# iostm32f205zx register map
Registers are 32-bit, access not given, no defined reset value unless marked. A register's access mark holds for its fields unless they carry their own. Addresses are absolute; registers are grouped by the start of their names; [hi:lo] are bit positions; {n}, {i} and the like mark numbered series.

## ADC2
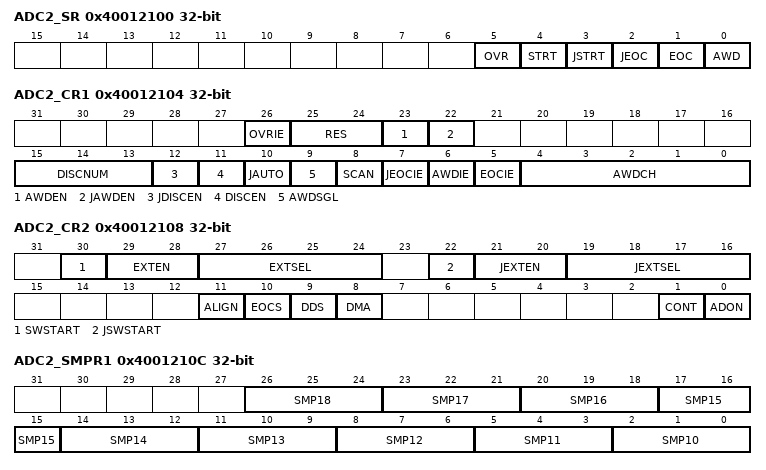
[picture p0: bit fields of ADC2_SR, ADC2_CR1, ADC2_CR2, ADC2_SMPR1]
0x40012100 ADC2_SR
  [5] OVR, [4] STRT, [3] JSTRT, [2] JEOC, [1] EOC, [0] AWD
0x40012104 ADC2_CR1
  [26] OVRIE, [25:24] RES, [23] AWDEN, [22] JAWDEN, [15:13] DISCNUM, [12] JDISCEN, [11] DISCEN, [10] JAUTO, [9] AWDSGL, [8] SCAN, [7] JEOCIE, [6] AWDIE, [5] EOCIE, [4:0] AWDCH
0x40012108 ADC2_CR2
  [30] SWSTART, [29:28] EXTEN, [27:24] EXTSEL, [22] JSWSTART, [21:20] JEXTEN, [19:16] JEXTSEL, [11] ALIGN, [10] EOCS, [9] DDS, [8] DMA, [1] CONT, [0] ADON
0x4001210C ADC2_SMPR1
  [3n-28:3n-30] SMP{n} (n=10..18)
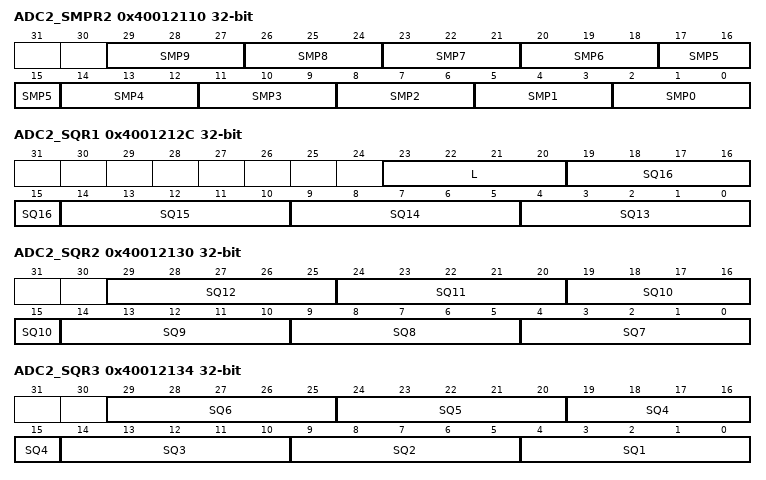
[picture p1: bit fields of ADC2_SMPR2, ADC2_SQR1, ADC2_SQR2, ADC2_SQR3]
0x40012110 ADC2_SMPR2
  [3n+2:3n] SMP{n} (n=0..9)
{0x40012110+4i} ADC2_JOFR{i} (i=1..4)
  [11:0] JOFFSET
0x40012124 ADC2_HTR
  [11:0] HT
0x40012128 ADC2_LTR
  [11:0] LT
0x4001212C ADC2_SQR1
  [23:20] L, [5n-61:5n-65] SQ{n} (n=13..16)
0x40012130 ADC2_SQR2
  [5n-31:5n-35] SQ{n} (n=7..12)
0x40012134 ADC2_SQR3
  [5n-1:5n-5] SQ{n} (n=1..6)
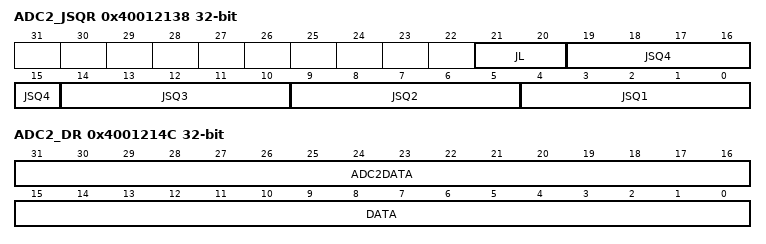
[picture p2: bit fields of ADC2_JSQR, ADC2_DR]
0x40012138 ADC2_JSQR
  [21:20] JL, [5n-1:5n-5] JSQ{n} (n=1..4)
{0x40012138+4i} ADC2_JDR{i} (i=1..4)
  [15:0] JDATA
0x4001214C ADC2_DR
  [31:16] ADC2DATA, [15:0] DATA

## ADC3
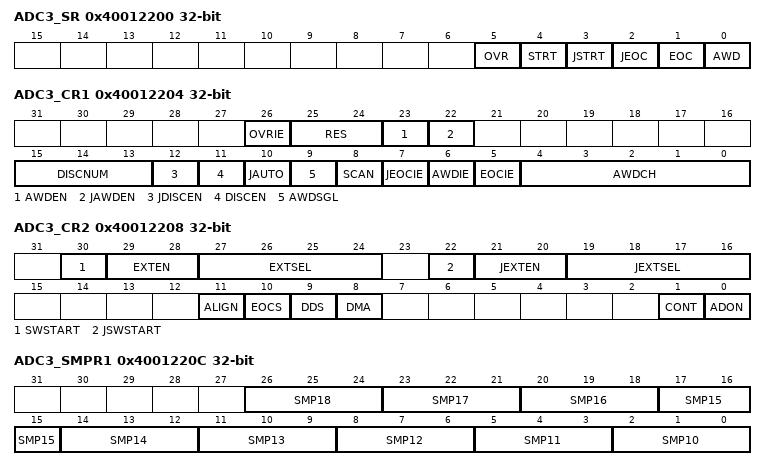
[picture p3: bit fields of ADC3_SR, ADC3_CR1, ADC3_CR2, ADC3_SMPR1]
0x40012200 ADC3_SR
  [5] OVR, [4] STRT, [3] JSTRT, [2] JEOC, [1] EOC, [0] AWD
0x40012204 ADC3_CR1
  [26] OVRIE, [25:24] RES, [23] AWDEN, [22] JAWDEN, [15:13] DISCNUM, [12] JDISCEN, [11] DISCEN, [10] JAUTO, [9] AWDSGL, [8] SCAN, [7] JEOCIE, [6] AWDIE, [5] EOCIE, [4:0] AWDCH
0x40012208 ADC3_CR2
  [30] SWSTART, [29:28] EXTEN, [27:24] EXTSEL, [22] JSWSTART, [21:20] JEXTEN, [19:16] JEXTSEL, [11] ALIGN, [10] EOCS, [9] DDS, [8] DMA, [1] CONT, [0] ADON
0x4001220C ADC3_SMPR1
  [3n-28:3n-30] SMP{n} (n=10..18)
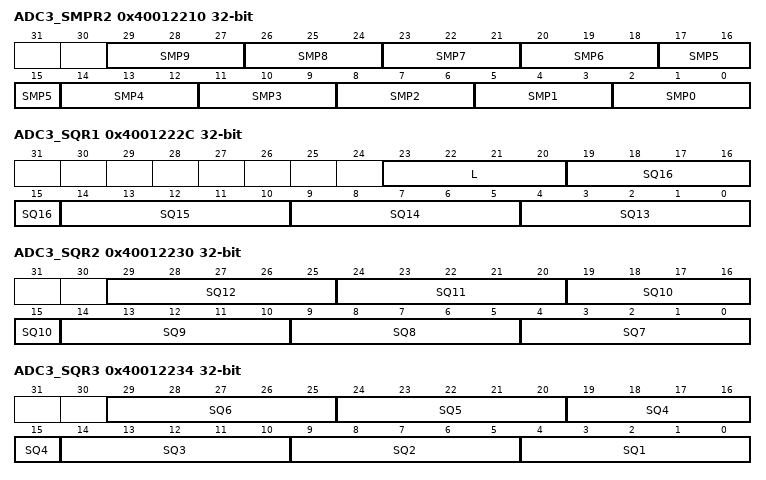
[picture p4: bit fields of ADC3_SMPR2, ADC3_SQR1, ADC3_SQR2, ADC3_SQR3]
0x40012210 ADC3_SMPR2
  [3n+2:3n] SMP{n} (n=0..9)
{0x40012210+4i} ADC3_JOFR{i} (i=1..4)
  [11:0] JOFFSET
0x40012224 ADC3_HTR
  [11:0] HT
0x40012228 ADC3_LTR
  [11:0] LT
0x4001222C ADC3_SQR1
  [23:20] L, [5n-61:5n-65] SQ{n} (n=13..16)
0x40012230 ADC3_SQR2
  [5n-31:5n-35] SQ{n} (n=7..12)
0x40012234 ADC3_SQR3
  [5n-1:5n-5] SQ{n} (n=1..6)
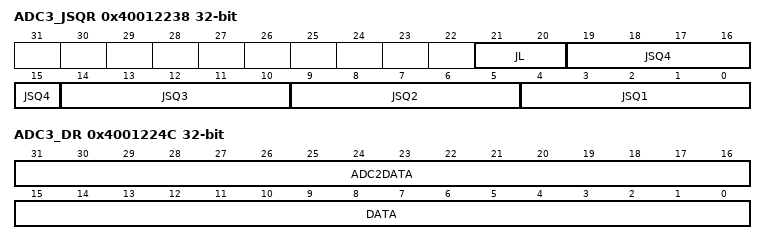
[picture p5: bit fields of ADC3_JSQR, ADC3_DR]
0x40012238 ADC3_JSQR
  [21:20] JL, [5n-1:5n-5] JSQ{n} (n=1..4)
{0x40012238+4i} ADC3_JDR{i} (i=1..4)
  [15:0] JDATA
0x4001224C ADC3_DR
  [31:16] ADC2DATA, [15:0] DATA

## DAC
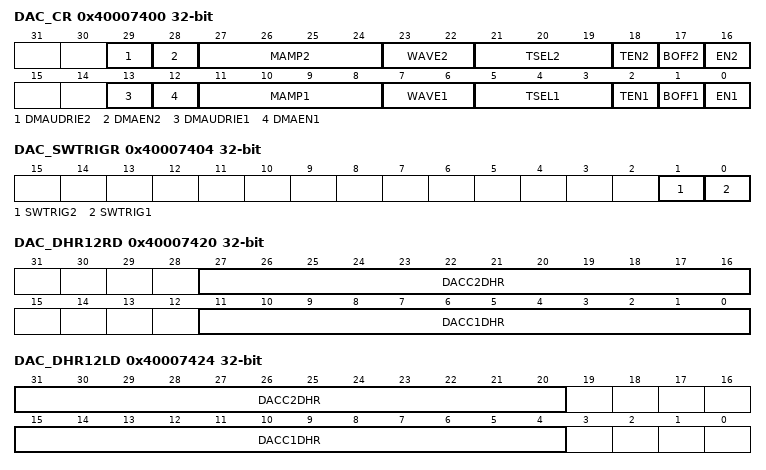
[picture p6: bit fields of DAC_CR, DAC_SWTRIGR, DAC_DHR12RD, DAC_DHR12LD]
0x40007400 DAC_CR
  [29] DMAUDRIE2, [28] DMAEN2, [27:24] MAMP2, [23:22] WAVE2, [21:19] TSEL2, [18] TEN2, [17] BOFF2, [16] EN2, [13] DMAUDRIE1, [12] DMAEN1, [11:8] MAMP1, [7:6] WAVE1, [5:3] TSEL1, [2] TEN1, [1] BOFF1, [0] EN1
0x40007404 DAC_SWTRIGR
  [1] SWTRIG2, [0] SWTRIG1
0x40007408 DAC_DHR12R1
  [11:0] DACC1DHR
0x4000740C DAC_DHR12L1
  [15:4] DACC1DHR
0x40007410 DAC_DHR8R1
  [7:0] DACC1DHR
0x40007414 DAC_DHR12R2
  [11:0] DACC2DHR
0x40007418 DAC_DHR12L2
  [15:4] DACC2DHR
0x4000741C DAC_DHR8R2
  [7:0] DACC2DHR
0x40007420 DAC_DHR12RD
  [27:16] DACC2DHR, [11:0] DACC1DHR
0x40007424 DAC_DHR12LD
  [31:20] DACC2DHR, [15:4] DACC1DHR
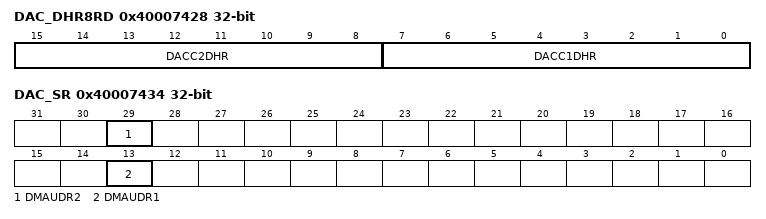
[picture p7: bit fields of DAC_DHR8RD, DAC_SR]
0x40007428 DAC_DHR8RD
  [15:8] DACC2DHR, [7:0] DACC1DHR
0x4000742C DAC_DOR1
  [11:0] DACC1DOR
0x40007430 DAC_DOR2
  [11:0] DACC2DOR
0x40007434 DAC_SR
  [29] DMAUDR2, [13] DMAUDR1

## FLASH
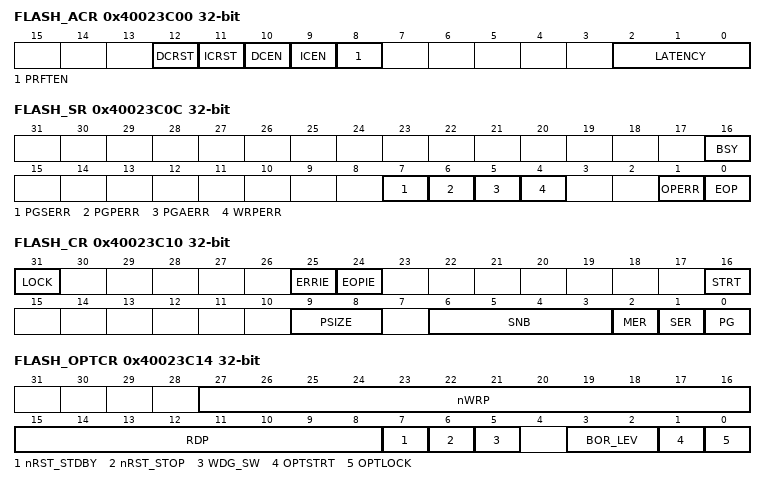
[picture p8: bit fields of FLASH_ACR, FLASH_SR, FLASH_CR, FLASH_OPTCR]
0x40023C00 FLASH_ACR
  [12] DCRST, [11] ICRST, [10] DCEN, [9] ICEN, [8] PRFTEN, [2:0] LATENCY
0x40023C04 FLASH_KEYR
0x40023C08 FLASH_OPTKEYR
0x40023C0C FLASH_SR
  [16] BSY, [7] PGSERR, [6] PGPERR, [5] PGAERR, [4] WRPERR, [1] OPERR, [0] EOP
0x40023C10 FLASH_CR
  [31] LOCK, [25] ERRIE, [24] EOPIE, [16] STRT, [9:8] PSIZE, [6:3] SNB, [2] MER, [1] SER, [0] PG
0x40023C14 FLASH_OPTCR
  [27:16] nWRP, [15:8] RDP, [7] nRST_STDBY, [6] nRST_STOP, [5] WDG_SW, [3:2] BOR_LEV, [1] OPTSTRT, [0] OPTLOCK

## CRC
0x40023000 CRC_DR
0x40023004 CRC_IDR
  [7:0] IDR
0x40023008 CRC_CR
  [0] RESET

## FSMC
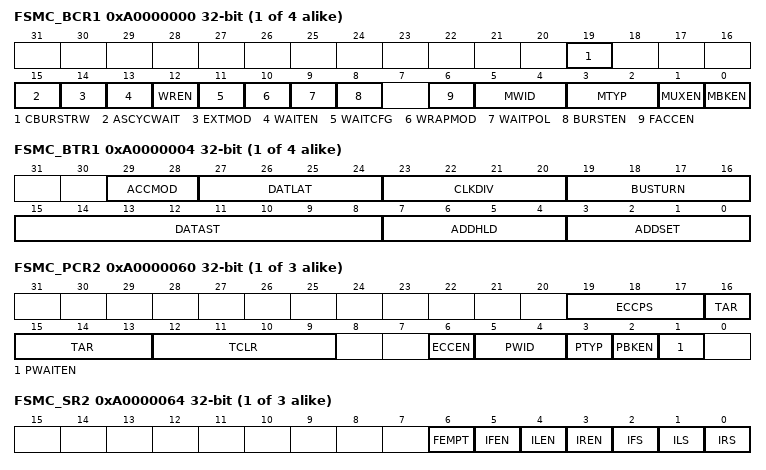
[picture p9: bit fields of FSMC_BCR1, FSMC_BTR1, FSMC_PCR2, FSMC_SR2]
{0x9FFFFFF8+8i} FSMC_BCR{i} (i=1..4)
  [19] CBURSTRW, [15] ASCYCWAIT, [14] EXTMOD, [13] WAITEN, [12] WREN, [11] WAITCFG, [10] WRAPMOD, [9] WAITPOL, [8] BURSTEN, [6] FACCEN, [5:4] MWID, [3:2] MTYP, [1] MUXEN, [0] MBKEN
{0x9FFFFFFC+8i} FSMC_BTR{i} (i=1..4)
  [29:28] ACCMOD, [27:24] DATLAT, [23:20] CLKDIV, [19:16] BUSTURN, [15:8] DATAST, [7:4] ADDHLD, [3:0] ADDSET
{0xA0000020+0x20*i} FSMC_PCR{i} (i=2..4)
  [19:17] ECCPS, [16:13] TAR, [12:9] TCLR, [6] ECCEN, [5:4] PWID, [3] PTYP, [2] PBKEN, [1] PWAITEN
{0xA0000024+0x20*i} FSMC_SR{i} (i=2..4)
  [6] FEMPT, [5] IFEN, [4] ILEN, [3] IREN, [2] IFS, [1] ILS, [0] IRS
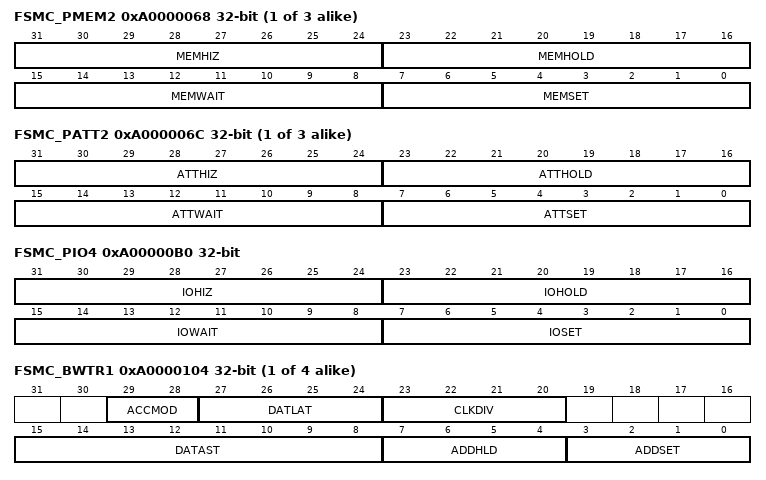
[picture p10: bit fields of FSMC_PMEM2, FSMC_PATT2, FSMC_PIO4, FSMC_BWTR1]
{0xA0000028+0x20*i} FSMC_PMEM{i} (i=2..4)
  [31:24] MEMHIZ, [23:16] MEMHOLD, [15:8] MEMWAIT, [7:0] MEMSET
{0xA000002C+0x20*i} FSMC_PATT{i} (i=2..4)
  [31:24] ATTHIZ, [23:16] ATTHOLD, [15:8] ATTWAIT, [7:0] ATTSET
0xA0000074 FSMC_ECCR2
0xA0000094 FSMC_ECCR3
0xA00000B0 FSMC_PIO4
  [31:24] IOHIZ, [23:16] IOHOLD, [15:8] IOWAIT, [7:0] IOSET
{0xA00000FC+8i} FSMC_BWTR{i} (i=1..4)
  [29:28] ACCMOD, [27:24] DATLAT, [23:20] CLKDIV, [15:8] DATAST, [7:4] ADDHLD, [3:0] ADDSET
